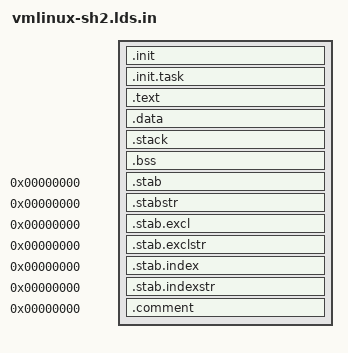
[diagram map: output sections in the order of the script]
/* ld script to make ARM Linux kernel
 * taken from the i386 version by Russell King
 * Written by Martin Mares <mj@atrey.karlin.mff.cuni.cz>
 */
OUTPUT_ARCH(sh)
ENTRY(stext)
SECTIONS
{
	. = TEXTADDR;

	.init : {
		_stext = .;
		__init_begin = .;	/* Init code and data		*/
			*(.text.init)
		__proc_info_begin = .;
			*(.proc.info)
		__proc_info_end = .;
		__arch_info_begin = .;
			*(.arch.info)
		__arch_info_end = .;
			*(.data.init)
		. = ALIGN(16);
		__setup_start = .;
			*(.setup.init)
		__setup_end = .;
		__initcall_start = .;
			*(.initcall.init)
		__initcall_end = .;
                __machvec_start = .;
                        *(.machvec.init)
                __machvec_end = .;
		. = ALIGN(4096);
		__init_end = .;
	}

	.init.task : {
		*(.init.task)
	}

	/DISCARD/ : {			/* Exit code and data		*/
		*(.text.exit)
		*(.data.exit)
		*(.exitcall.exit)
	}

	.text : {
		_text = .;		/* Text and read-only data	*/
			*(.text)
			*(.fixup)
			*(.gnu.warning)
			*(.text.lock)	/* out-of-line lock text */
			*(.rodata)
			*(.glue_7)
			*(.glue_7t)
			*(.kstrtab)
		. = ALIGN(16);		/* Exception table		*/
		__start___ex_table = .;
			*(__ex_table)
		__stop___ex_table = .;

		__start___ksymtab = .;	/* Kernel symbol table		*/
			*(__ksymtab)
		__stop___ksymtab = .;

		*(.got)			/* Global offset table		*/

		_etext = .;		/* End of text section		*/
	}

	.data : {
		/*
		 * The cacheline aligned data
		 */
		. = ALIGN(32);
		*(.data.cacheline_aligned)

		/*
		 * and the usual data section
		 */
		*(.data)
		CONSTRUCTORS

		_edata = .;
	}

        .stack : {
	        stack = .;
		_stack = .;
	}
    
	.bss : {
		__bss_start = .;	/* BSS				*/
		*(.bss)
		*(COMMON)
		_end = . ;
	}

        . = ALIGN(8192);
        _end_kernel = . ;
	
	/* Stabs debugging sections.	*/
	.stab 0 : { *(.stab) }
	.stabstr 0 : { *(.stabstr) }
	.stab.excl 0 : { *(.stab.excl) }
	.stab.exclstr 0 : { *(.stab.exclstr) }
	.stab.index 0 : { *(.stab.index) }
	.stab.indexstr 0 : { *(.stab.indexstr) }
	.comment 0 : { *(.comment) }
}
